# Musca_B1 register map
Vendor: ARM Ltd.; Series: ARMv8-M Mainline; File version: 1.0
CPU: CM33 r0p2, little endian, MPU, FPU, 4 interrupt priority bits, 8 SAU regions
Registers are 32-bit, read-write, reset 0x0 unless marked. A register's access mark holds for its fields unless they carry their own. Offsets are from the block's base; [hi:lo] are bit positions; {n}, {i} and the like mark numbered series.

## SCC — Serial Communication Controller
Base 0x5010B000
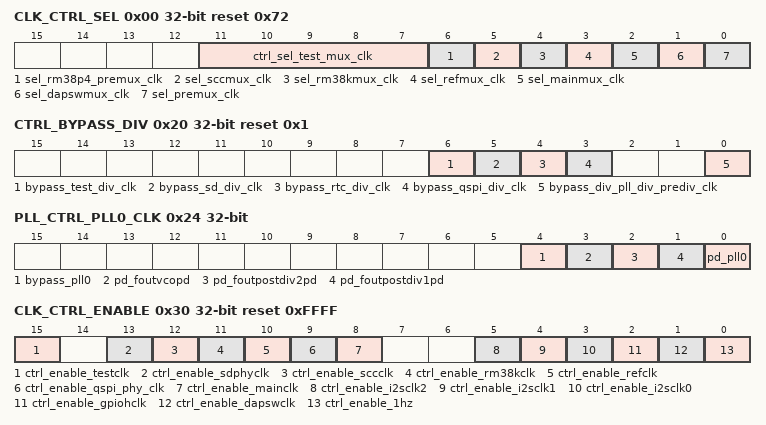
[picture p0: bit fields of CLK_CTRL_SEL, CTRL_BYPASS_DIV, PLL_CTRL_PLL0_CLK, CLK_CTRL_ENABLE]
0x00 CLK_CTRL_SEL reset 0x72
  [11:7] ctrl_sel_test_mux_clk
  [6] sel_rm38p4_premux_clk — 0: SYSSYSSUGCLK 1: NRM138P4
  [5] sel_sccmux_clk — 0: SCCCLK 1: PRE_MUX_CLK
  [4] sel_rm38kmux_clk — 0: REF_MUX_CLK 1: RM38K
  [3] sel_refmux_clk — 0: PRE_MUX_CLK 1: PRE_PLL_CLK
  [2] sel_mainmux_clk — 0: PLL0_CLK 1: PRE_MUX_CLK
  [1] sel_dapswmux_clk — 0: PRE_MUX_CLK 1: TCK
  [0] sel_premux_clk — 0: 32k 1: FASTCLK
0x04 CLK_PLL_PREDIV_CTRL
  [9:0] prediv_ctrl
0x0C CLK_POSTDIV_CTRL_FLASH reset 0x1
  [7:0] postdiv_ctrl_flash_div
0x10 CLK_POSTDIV_CTRL_QSPI reset 0x1
  [7:0] postdiv_ctrl_qspi_div
0x14 CLK_POSTDIV_CTRL_RTC reset 0xFFFFFFFF
  [31:0] postdiv_ctrl_rtc_div
0x18 CLK_POSTDIV_CTRL_SD reset 0x1
  [7:0] postdiv_ctrl_sd_div
0x1C CLK_POSTDIV_CTRL_TEST reset 0xA
  [7:0] postdiv_ctrl_test_div
0x20 CTRL_BYPASS_DIV reset 0x1
  [6] bypass_test_div_clk — 0: Not bypass 1: bypass
  [5] bypass_sd_div_clk — 0: Not bypass 1: bypass
  [4] bypass_rtc_div_clk — 0: Not bypass 1: bypass
  [3] bypass_qspi_div_clk — 0: Not bypass 1: bypass
  [0] bypass_div_pll_div_prediv_clk — 0: Not bypass 1: bypass
0x24 PLL_CTRL_PLL0_CLK
  [4] bypass_pll0
  [3] pd_foutvcopd — Power down FOUTVCOPD
  [2] pd_foutpostdiv2pd — Power down FOUTPOSTDIV2PD
  [1] pd_foutpostdiv1pd — Power down FOUTPOSTDIV1PD:
  [0] pd_pll0 — Power down PLL0
0x28 PLL_POSTDIV_CTRL_PLL0_CLK reset 0x1
  [3:0] pll_postdiv_ctrl_pll0_clk
0x2C PLL_CTRL_MULT_PLL0_CLK reset 0x1388
  [13:0] pll_mult_ctrl_pll0_clk
0x30 CLK_CTRL_ENABLE reset 0xFFFF
  [15] ctrl_enable_testclk — 0: Disable; 1: Enable
  [13] ctrl_enable_sdphyclk — 0: Disable; 1: Enable
  [12] ctrl_enable_sccclk — 0: Disable; 1: Enable
  [11] ctrl_enable_rm38kclk — 0: Disable; 1: Enable
  [10] ctrl_enable_refclk — 0: Disable; 1: Enable
  [9] ctrl_enable_qspi_phy_clk — 0: Disable; 1: Enable
  [8] ctrl_enable_mainclk — 0: Disable; 1: Enable
  [5] ctrl_enable_i2sclk2 — 0: Disable; 1: Enable
  [4] ctrl_enable_i2sclk1 — 0: Disable; 1: Enable
  [3] ctrl_enable_i2sclk0 — 0: Disable; 1: Enable
  [2] ctrl_enable_gpiohclk — 0: Disable; 1: Enable
  [1] ctrl_enable_dapswclk — 0: Disable; 1: Enable
  [0] ctrl_enable_1hz — 0: Disable; 1: Enable
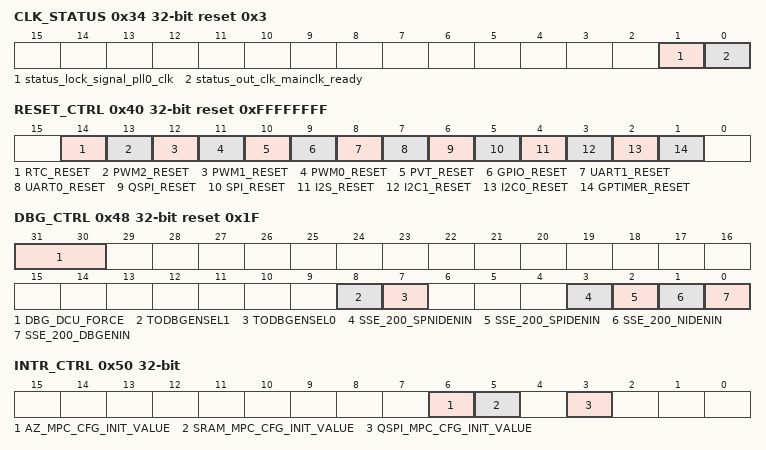
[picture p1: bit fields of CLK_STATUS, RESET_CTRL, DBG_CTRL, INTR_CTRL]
0x34 CLK_STATUS ro reset 0x3
  [1] status_lock_signal_pll0_clk — PLL Lock Status
  [0] status_out_clk_mainclk_ready — Clock ready (active)
0x40 RESET_CTRL reset 0xFFFFFFFF
  [14] RTC_RESET — Reset Active low
  [13] PWM2_RESET — Reset Active low
  [12] PWM1_RESET — Reset Active low
  [11] PWM0_RESET — Reset Active low
  [10] PVT_RESET — Reset Active low
  [9] GPIO_RESET — Reset Active low
  [8] UART1_RESET — Reset Active low
  [7] UART0_RESET — Reset Active low
  [6] QSPI_RESET — Reset Active low
  [5] SPI_RESET — Reset Active low
  [4] I2S_RESET — Reset Active low
  [3] I2C1_RESET — Reset Active low
  [2] I2C0_RESET — Reset Active low
  [1] GPTIMER_RESET — Reset Active low
0x48 DBG_CTRL reset 0x1F
  [31:30] DBG_DCU_FORCE — SSE-200 debug ports control
  [8] TODBGENSEL1 — 0: Enable 1: Mask or bypass
  [7] TODBGENSEL0 — 0: Enable 1: Mask or bypass
  [3] SSE_200_SPNIDENIN — 0: Not enable 1: Enable
  [2] SSE_200_SPIDENIN — 0: Not enable 1: Enable
  [1] SSE_200_NIDENIN — 0: Not enable 1: Enable
  [0] SSE_200_DBGENIN — 0: Not enable 1: Enable
0x4C SRAM_CTRL reset 0x48100000
  [15:0] CODE_SRAMx_PGEN — SRAM cell power gate enable
0x50 INTR_CTRL
  [6] AZ_MPC_CFG_INIT_VALUE — 0: Secure mode 1: Non-secure mode
  [5] SRAM_MPC_CFG_INIT_VALUE — 0: Secure mode 1: Non-secure mode
  [3] QSPI_MPC_CFG_INIT_VALUE — 0: Secure mode 1: Non-secure mode
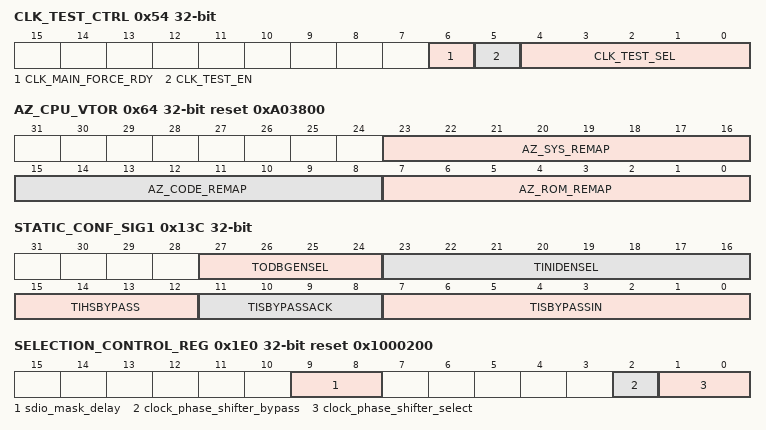
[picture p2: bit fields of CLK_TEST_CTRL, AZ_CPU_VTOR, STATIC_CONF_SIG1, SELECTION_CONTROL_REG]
0x54 CLK_TEST_CTRL
  [6] CLK_MAIN_FORCE_RDY
  [5] CLK_TEST_EN — 0: Not enable 1: Enable
  [4:0] CLK_TEST_SEL — Select TESTMUX input
0x58 CPU0_VTOR reset 0x10000000
  [31:7] CPU0_VTOR_SECURE — Reset vector for CPU0 secure mode
0x60 CPU1_VTOR reset 0x1A400000
  [31:7] CPU1_VTOR_SECURE — Reset vector for CPU1 secure mode
0x64 AZ_CPU_VTOR reset 0xA03800
  [23:16] AZ_SYS_REMAP — Remap vector for Alcatraz System address space
  [15:8] AZ_CODE_REMAP — Remap vector for Alcatraz Code address space
  [7:0] AZ_ROM_REMAP — Remap vector for Alcatraz ROM address space.
0x68 IOMUX_MAIN_INSEL_0 reset 0xFFFFFFFF
  [31:0] iomux_main_insel_0 — 0: Select ATF1 1: Select Main Function
0x6C IOMUX_MAIN_INSEL_1 reset 0xFFFFFFFF
  [5:0] iomux_main_insel_1 — 0: Select ATF1 1: Select Main Function
0x70 IOMUX_MAIN_OUTSEL_0 reset 0xFFFFFFFF
  [31:0] iomux_main_outsel_0 — 0: Select ATF1 1: Select Main Function
0x74 IOMUX_MAIN_OUTSEL_1 reset 0xFFFFFFFF
  [5:0] iomux_main_outsel_1 — 0: Select ATF1 1: Select Main Function
0x78 IOMUX_MAIN_OENSEL_0 reset 0xFFFFFFFF
  [31:0] iomux_main_oensel_0 — 0: Select ATF1 1: Select Main Function
0x7C IOMUX_MAIN_OENSEL_1 reset 0xFFFFFFFF
  [5:0] iomux_main_oensel_1 — 0: Select ATF1 1: Select Main Function
0x80 IOMUX_MAIN_DEFAULT_IN_0
  [31:0] iomux_main_default_in_0 — 0: Default to 0 1: Default to 1
0x84 IOMUX_MAIN_DEFAULT_IN_1
  [5:0] iomux_main_default_in_1 — 0: Default to 0 1: Default to 1
0x88 IOMUX_ALTF1_INSEL_0
  [31:0] iomux_altf1_insel_0 — 0: Select ATF2 1: Select ATF1
0x8C IOMUX_ALTF1_INSEL_1
  [5:0] iomux_altf1_insel_1 — 0: Select ATF2 1: Select ATF1
0x90 IOMUX_ALTF1_OUTSEL_0 reset 0xFFFFFFFF
  [31:0] iomux_altf1_outsel_0 — 0: Select ATF2 1: Select ATF1
0x94 IOMUX_ALTF1_OUTSEL_1 reset 0xFFFFFFFF
  [5:0] iomux_altf1_outsel_1 — 0: Select ATF2 1: Select ATF1
0x98 IOMUX_ALTF1_OENSEL_0 reset 0xFFFFFFFF
  [31:0] iomux_altf1_oensel_0 — 0: Select ATF2 1: Select ATF1
0x9C IOMUX_ALTF1_OENSEL_1 reset 0xFFFFFFFF
  [5:0] iomux_altf1_oensel_1 — 0: Select ATF2 1: Select ATF1
0xA0 IOMUX_ALTF1_DEFAULT_IN_0
  [31:0] iomux_altf1_default_in_0 — 0: Default to 0 1: Default to 1
0xA4 IOMUX_ALTF1_DEFAULT_IN_1
  [5:0] iomux_altf1_default_in_1 — 0: Default to 0 1: Default to 1
0xA8 IOMUX_ALTF2_INSEL_0
  [31:0] iomux_altf2_insel_0 — 0: Select ATF3 1: Select ATF2
0xAC IOMUX_ALTF2_INSEL_1 reset not defined
  [5:0] iomux_altf2_insel_1 — 0: Select ATF3 1: Select ATF2
0xB0 IOMUX_ALTF2_OUTSEL_0 reset 0xFFFFFFFF
  [31:0] iomux_altf2_outsel_0 — 0: Select ATF3 1: Select ATF2
0xB4 IOMUX_ALTF2_OUTSEL_1 reset 0xFFFFFFFF
  [5:0] iomux_altf2_outsel_1 — 0: Select ATF3 1: Select ATF2
0xB8 IOMUX_ALTF2_OENSEL_0 reset 0xFFFFFFFF
  [31:0] iomux_altf2_oensel_0 — 0: Select ATF3 1: Select ATF2
0xBC IOMUX_ALTF2_OENSEL_1 reset 0xFFFFFFFF
  [5:0] iomux_altf2_oensel_1 — 0: Select ATF3 1: Select ATF2
0xC0 IOMUX_ALTF2_DEFAULT_IN_0
  [31:0] iomux_altf2_default_in_0 — 0: Default to 0 1: Default to 1
0xC4 IOMUX_ALTF2_DEFAULT_IN_1
  [5:0] iomux_altf2_default_in_1 — 0: Default to 0 1: Default to 1
0xE8 IOPAD_DSO_0 reset 0xFFF00000
  [31:0] drive_strength0 — Least significant bits of the two-bit values that define drive strengths of test chip I/O PA31-PA0
0xEC IOPAD_DSO_1 reset 0xFFFFFFFF
  [5:0] drive_strength_0 — Least significant bits of the two-bit values that define drive strengths of test chip I/O PA37-PA32
0xF0 IOPAD_DS1_0 reset 0xFFFFFFFF
  [31:0] drive_strength1 — Most significant bits of the two-bit values that define drive strengths of test chip I/O PA31-PA0
0xF4 IOPAD_DS1_1 reset 0xFFFFFFFF
  [5:0] drive_strength_1 — Most significant bits of the two-bit values that define drive strengths of test chip I/O PA37-PA32
0xF8 IOPAD_PE_0 reset 0xFFFFFFFF
  [31:0] pull_enable — Enables pull resistors of test chip I/O PA31-PA0
0xFC IOPAD_PE_1 reset 0xFFFFFFFF
  [5:0] pull_enable — Enables pull resistors of test chip I/O PA37-PA32
0x100 IOPAD_PS_0 reset 0xFFFFFFFF
  [31:0] pull_select — Enables pull resistors of test chip I/O PA31-PA0
0x104 IOPAD_PS_1 reset 0xFFFFFFFF
  [5:0] pull_select — Enables pull resistors of test chip I/O PA37-PA32
0x108 IOPAD_SR_0 reset 0xFFFFFFFF
  [31:0] slew_rate — Selects the slew rate of test chip I/O PA31-PA0
0x10C IOPAD_SR_1 reset 0xFFFFFFFF
  [5:0] slew_rate — Selects the slew rate of test chip I/O PA37-PA32
0x110 IOPAD_IS_0 reset 0xFFFFFFFF
  [31:0] input_select — Selects input mode on test chip I/O PA31-PA0
0x114 IOPAD_IS_1 reset 0xFFFFFFFF
  [5:0] input_select — Selects input mode on test chip I/O PA37-PA32
0x118 PVT_CTRL
  [4:0] TSTSENNUM — Select PVT sensor to write to and read from
0x130 SPARE0
  [31:0] spare0 — Spare read-write register for software
0x13C STATIC_CONF_SIG1
  [27:24] TODBGENSEL — DBGEN mask on CTITRIGOUT
  [23:16] TINIDENSEL — NIDEN mask on CTITRIGINT
  [15:12] TIHSBYPASS — Cross Trigger Interface handshake bypass on CTITRIGOUT
  [11:8] TISBYPASSACK — Cross Trigger Interface synchronous bypass on CTITRIGOUTACK
  [7:0] TISBYPASSIN — Cross Trigger Interface synchronous bypass on CTITRIGIN
0x1A0 FLASH_DIN_0
  [31:0] scc_flash_din0 — eFlash 0 and eFlash 1 data input[31:0]
0x1A4 FLASH_DIN_1
  [31:0] scc_flash_din1 — eFlash 0 and eFlash 1 data input{63:32]
0x1A8 FLASH_DIN_2
  [31:0] scc_flash_din2 — eFlash 0 and eFlash 1 data input[95:64]
0x1AC FLASH_DIN_3
  [31:0] scc_flash_din3 — eFlash 0 and eFlash 1 data input[127:96]
{0x1C0+4i} FLASH0_DOUT_{i} ro reset 0xFFFFFFFF (i=0..3)
  [31:0] scc_flash0_dout{i} — eFlash 0 data output[{32i+31}:{32i}]
{0x1D0+4i} FLASH1_DOUT_{i} ro reset 0xFFFFFFFF (i=0..3)
  [31:0] scc_flash1_dout{i} — eFlash 1 data output[{32i+31}:{32i}]
0x1E0 SELECTION_CONTROL_REG reset 0x1000200
  [9:8] sdio_mask_delay
  [2] clock_phase_shifter_bypass — QSPI input clock phase shift control
  [1:0] clock_phase_shifter_select — QSPI input clock phase shift control
0x1E4 AZ_ROM_REMAP_MASK reset 0x1FFFF
  [31:0] az_rom_remap_mask — Alcatraz ROM remap mask
0x1E8 AZ_ROM_REMAP_OFFSET reset 0x1A200000
  [31:0] az_rom_remap_offset — Alcatraz ROM remap offset
0x1EC AZ_CODE_REMAP_MASK reset 0xFFFFFF
  [31:0] az_code_remap_mask — Alcatraz code remap mask
0x1F0 AZ_CODE_REMAP_OFFSET
  [31:0] az_code_remap_offset — Alcatraz code remap offset
0x1F4 AZ_SYS_REMAP_MASK reset 0x3FFFF
  [31:0] az_sys_remap_mask — Alcatraz system remap mask
0x1F8 AZ_SYS_REMAP_OFFSET reset 0x40010000
  [31:0] az_sys_remap_offset — Alcatraz system remap offset
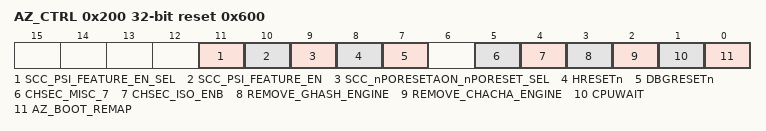
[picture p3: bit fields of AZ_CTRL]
0x200 AZ_CTRL reset 0x600
  [11] SCC_PSI_FEATURE_EN_SEL — Select PSI_FEATURE_EN source
  [10] SCC_PSI_FEATURE_EN — Value of SCC_PSI_FEATURE_EN from SCC
  [9] SCC_nPORESETAON_nPORESET_SEL — Alcatraz reset control
  [8] HRESETn — Alcatraz reset HRESETn
  [7] DBGRESETn — Alcatraz reset DBGRESETn
  [5] CHSEC_MISC_7 — Alcatraz CryptoCell secure Secure Frame control
  [4] CHSEC_ISO_ENB — Alcatraz CryptoCell Secure Frame Isolation enable
  [3] REMOVE_GHASH_ENGINE — Alcatraz CryptoCell remove Ghash engine
  [2] REMOVE_CHACHA_ENGINE — Alcatraz CryptoCell remove CHACHA engine
  [1] CPUWAIT — Alcatraz CPU wait at boot:
  [0] AZ_BOOT_REMAP — Alcatraz remap at boot
0x208 SSE_OTP_RD_DATA ro
  [31:0] sse_otp_rd_data — SSE-200 OTP read data
0x210 AZ_OTP_RD_DATA
  [31:0] az_otp_rd_data — Alcatraz OTP read data
0x21C SPARE_CTRL0
  [31:0] spare_ctrl0 — Spare control register
0x220 SPARE_CTRL1
  [31:0] spare_ctrl1 — Spare control register
0x400 CHIP_ID ro reset 0x7D00477
  [31:0] chip_id — Component ID information

## Notices in the file
Copyright (C) 2012-2018 ARM Limited. All rights reserved.
Purpose: System Viewer Description (SVD) Example (Schema Version 1.1)
This is a description of a none-existent and incomplete device
for demonstration purposes only.
Redistribution and use in source and binary forms, with or without
modification, are permitted provided that the following conditions are met:
- Redistributions of source code must retain the above copyright
notice, this list of conditions and the following disclaimer.
- Redistributions in binary form must reproduce the above copyright
notice, this list of conditions and the following disclaimer in the
documentation and/or other materials provided with the distribution.
- Neither the name of ARM nor the names of its contributors may be used
to endorse or promote products derived from this software without
specific prior written permission.
THIS SOFTWARE IS PROVIDED BY THE COPYRIGHT HOLDERS AND CONTRIBUTORS "AS IS"
AND ANY EXPRESS OR IMPLIED WARRANTIES, INCLUDING, BUT NOT LIMITED TO, THE
IMPLIED WARRANTIES OF MERCHANTABILITY AND FITNESS FOR A PARTICULAR PURPOSE
ARE DISCLAIMED. IN NO EVENT SHALL COPYRIGHT HOLDERS AND CONTRIBUTORS BE
LIABLE FOR ANY DIRECT, INDIRECT, INCIDENTAL, SPECIAL, EXEMPLARY, OR
CONSEQUENTIAL DAMAGES (INCLUDING, BUT NOT LIMITED TO, PROCUREMENT OF
SUBSTITUTE GOODS OR SERVICES; LOSS OF USE, DATA, OR PROFITS; OR BUSINESS
INTERRUPTION) HOWEVER CAUSED AND ON ANY THEORY OF LIABILITY, WHETHER IN
CONTRACT, STRICT LIABILITY, OR TORT (INCLUDING NEGLIGENCE OR OTHERWISE)
ARISING IN ANY WAY OUT OF THE USE OF THIS SOFTWARE, EVEN IF ADVISED OF THE
POSSIBILITY OF SUCH DAMAGE.
